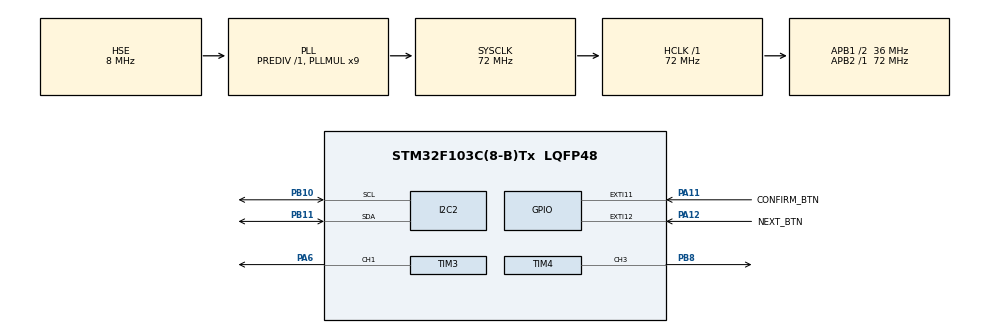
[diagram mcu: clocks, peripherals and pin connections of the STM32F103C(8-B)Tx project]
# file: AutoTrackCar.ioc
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Dma.I2C2_TX.0.Direction=DMA_MEMORY_TO_PERIPH
Dma.I2C2_TX.0.Instance=DMA1_Channel4
Dma.I2C2_TX.0.MemDataAlignment=DMA_MDATAALIGN_BYTE
Dma.I2C2_TX.0.MemInc=DMA_MINC_ENABLE
Dma.I2C2_TX.0.Mode=DMA_NORMAL
Dma.I2C2_TX.0.PeriphDataAlignment=DMA_PDATAALIGN_BYTE
Dma.I2C2_TX.0.PeriphInc=DMA_PINC_DISABLE
Dma.I2C2_TX.0.Priority=DMA_PRIORITY_LOW
Dma.Request0=I2C2_TX
Dma.Request1=TIM3_CH4/UP
Dma.Request2=TIM3_CH1/TRIG
Dma.TIM3_CH1/TRIG.2.Direction=DMA_PERIPH_TO_MEMORY
Dma.TIM3_CH1/TRIG.2.Instance=DMA1_Channel6
Dma.TIM3_CH1/TRIG.2.MemDataAlignment=DMA_MDATAALIGN_HALFWORD
Dma.TIM3_CH1/TRIG.2.MemInc=DMA_MINC_ENABLE
Dma.TIM3_CH1/TRIG.2.Mode=DMA_NORMAL
Dma.TIM3_CH1/TRIG.2.PeriphDataAlignment=DMA_PDATAALIGN_HALFWORD
Dma.TIM3_CH1/TRIG.2.PeriphInc=DMA_PINC_DISABLE
Dma.TIM3_CH1/TRIG.2.Priority=DMA_PRIORITY_LOW
Dma.TIM3_CH4/UP.1.Direction=DMA_PERIPH_TO_MEMORY
Dma.TIM3_CH4/UP.1.Instance=DMA1_Channel3
Dma.TIM3_CH4/UP.1.MemDataAlignment=DMA_MDATAALIGN_HALFWORD
Dma.TIM3_CH4/UP.1.MemInc=DMA_MINC_ENABLE
Dma.TIM3_CH4/UP.1.Mode=DMA_NORMAL
Dma.TIM3_CH4/UP.1.PeriphDataAlignment=DMA_PDATAALIGN_HALFWORD
Dma.TIM3_CH4/UP.1.PeriphInc=DMA_PINC_DISABLE
Dma.TIM3_CH4/UP.1.Priority=DMA_PRIORITY_LOW
I2C2.I2C_Mode=I2C_Fast
Mcu.Family=STM32F1
Mcu.Name=STM32F103C(8-B)Tx
Mcu.Package=LQFP48
NVIC.DMA1_Channel3_IRQn=true\:0\:0\:false\:false\:true\:false\:true\:true
NVIC.DMA1_Channel4_IRQn=true\:0\:0\:false\:false\:true\:false\:true\:true
NVIC.DMA1_Channel6_IRQn=true\:0\:0\:false\:false\:true\:false\:true\:true
NVIC.EXTI15_10_IRQn=true\:0\:0\:false\:false\:true\:true\:true\:true
NVIC.I2C2_ER_IRQn=true\:0\:0\:false\:false\:true\:true\:true\:true
NVIC.I2C2_EV_IRQn=true\:0\:0\:false\:false\:true\:true\:true\:true
NVIC.PriorityGroup=NVIC_PRIORITYGROUP_4
NVIC.TIM3_IRQn=true\:0\:0\:false\:false\:true\:true\:true\:true
PA11.GPIO_Label=CONFIRM_BTN
PA11.GPIO_ModeDefaultEXTI=GPIO_MODE_IT_FALLING
PA11.GPIO_PuPd=GPIO_PULLUP
PA11.Signal=GPXTI11
PA12.GPIO_Label=NEXT_BTN
PA12.GPIO_ModeDefaultEXTI=GPIO_MODE_IT_FALLING
PA12.GPIO_PuPd=GPIO_PULLUP
PA12.Signal=GPXTI12
PA13.Mode=Serial_Wire
PA13.Signal=SYS_JTMS-SWDIO
PA14.Mode=Serial_Wire
PA14.Signal=SYS_JTCK-SWCLK
PA6.Signal=S_TIM3_CH1
PB10.Mode=I2C
PB10.Signal=I2C2_SCL
PB11.Mode=I2C
PB11.Signal=I2C2_SDA
PB8.Signal=S_TIM4_CH3
PD0-OSC_IN.Mode=HSE-External-Oscillator
PD0-OSC_IN.Signal=RCC_OSC_IN
PD1-OSC_OUT.Mode=HSE-External-Oscillator
PD1-OSC_OUT.Signal=RCC_OSC_OUT
ProjectManager.HeapSize=0x200
ProjectManager.StackSize=0x400
ProjectManager.TargetToolchain=MDK-ARM V5.32
RCC.AHBFreq_Value=72000000
RCC.APB1CLKDivider=RCC_HCLK_DIV2
RCC.APB1Freq_Value=36000000
RCC.APB1TimFreq_Value=72000000
RCC.APB2Freq_Value=72000000
RCC.APB2TimFreq_Value=72000000
RCC.EnbaleCSS=true
RCC.HCLKFreq_Value=72000000
RCC.PLLMUL=RCC_PLL_MUL9
RCC.PLLSourceVirtual=RCC_PLLSOURCE_HSE
RCC.SYSCLKFreq_VALUE=72000000
RCC.SYSCLKSource=RCC_SYSCLKSOURCE_PLLCLK
RCC.USBFreq_Value=72000000
SH.S_TIM3_CH1.0=TIM3_CH1,PWM Generation1 CH1
SH.S_TIM4_CH3.0=TIM4_CH3,PWM Generation3 CH3
TIM3.Channel-PWM\ Generation1\ CH1=TIM_CHANNEL_1
TIM3.Period=2000-1
TIM3.Prescaler=720-1
TIM3.Pulse-PWM\ Generation1\ CH1=150
TIM4.Channel-PWM\ Generation3\ CH3=TIM_CHANNEL_3
TIM4.OCMode_PWM-PWM\ Generation3\ CH3=TIM_OCMODE_PWM1
TIM4.Period=2000-1
TIM4.Prescaler=720-1
TIM4.Pulse-PWM\ Generation3\ CH3=150
VP_TIM3_VS_ClockSourceINT.Mode=Internal
VP_TIM4_VS_ClockSourceINT.Mode=Internal
board=custom

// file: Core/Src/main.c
/* USER CODE BEGIN Header */
/**
  ******************************************************************************
  * @file           : main.c
  * @brief          : Main program body
  ******************************************************************************
  * @attention
  *
  * Copyright (c) 2026 STMicroelectronics.
  * All rights reserved.
  *
  * This software is licensed under terms that can be found in the LICENSE file
  * in the root directory of this software component.
  * If no LICENSE file comes with this software, it is provided AS-IS.
  *
  ******************************************************************************
  */
/* USER CODE END Header */
#include "main.h"
#include "dma.h"
#include "i2c.h"
#include "tim.h"
#include "gpio.h"

/* USER CODE BEGIN Includes */
#include "app_state.h"
/* USER CODE END Includes */

void SystemClock_Config(void);

int main(void)
{

  /* MCU Configuration--------------------------------------------------------*/

  /* Reset of all peripherals, Initializes the Flash interface and the Systick. */
  HAL_Init();

  /* Configure the system clock */
  SystemClock_Config();

  /* Initialize all configured peripherals */
  MX_GPIO_Init();
  MX_DMA_Init();
  MX_I2C2_Init();
  MX_TIM3_Init();
  MX_TIM4_Init();

  /* Infinite loop */
  /* USER CODE BEGIN WHILE */
  while (1)
  {
      StateMachine_Run();
    /* USER CODE END WHILE */

  }
}

void SystemClock_Config(void)
{
  RCC_OscInitTypeDef RCC_OscInitStruct = {0};
  RCC_ClkInitTypeDef RCC_ClkInitStruct = {0};

  /** Initializes the RCC Oscillators according to the specified parameters
  * in the RCC_OscInitTypeDef structure.
  */
  RCC_OscInitStruct.OscillatorType = RCC_OSCILLATORTYPE_HSE;
  RCC_OscInitStruct.HSEState = RCC_HSE_ON;
  RCC_OscInitStruct.HSEPredivValue = RCC_HSE_PREDIV_DIV1;
  RCC_OscInitStruct.HSIState = RCC_HSI_ON;
  RCC_OscInitStruct.PLL.PLLState = RCC_PLL_ON;
  RCC_OscInitStruct.PLL.PLLSource = RCC_PLLSOURCE_HSE;
  RCC_OscInitStruct.PLL.PLLMUL = RCC_PLL_MUL9;
  if (HAL_RCC_OscConfig(&RCC_OscInitStruct) != HAL_OK)
  {
    Error_Handler();
  }

  /** Initializes the CPU, AHB and APB buses clocks
  */
  RCC_ClkInitStruct.ClockType = RCC_CLOCKTYPE_HCLK|RCC_CLOCKTYPE_SYSCLK
                              |RCC_CLOCKTYPE_PCLK1|RCC_CLOCKTYPE_PCLK2;
  RCC_ClkInitStruct.SYSCLKSource = RCC_SYSCLKSOURCE_PLLCLK;
  RCC_ClkInitStruct.AHBCLKDivider = RCC_SYSCLK_DIV1;
  RCC_ClkInitStruct.APB1CLKDivider = RCC_HCLK_DIV2;
  RCC_ClkInitStruct.APB2CLKDivider = RCC_HCLK_DIV1;

  if (HAL_RCC_ClockConfig(&RCC_ClkInitStruct, FLASH_LATENCY_2) != HAL_OK)
  {
    Error_Handler();
  }

  /** Enables the Clock Security System
  */
  HAL_RCC_EnableCSS();
}

void Error_Handler(void)
{
  __disable_irq();
  while (1)
  {
  }
}
